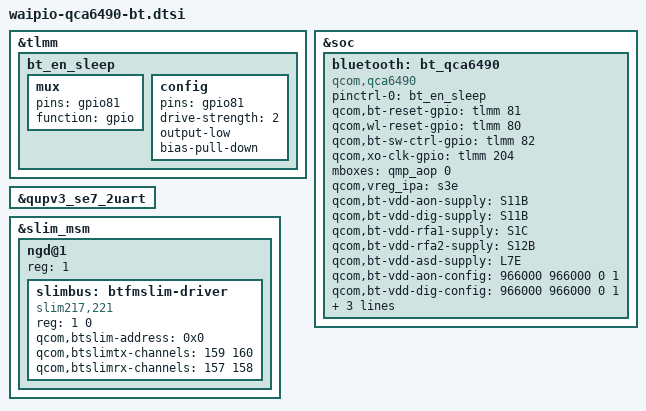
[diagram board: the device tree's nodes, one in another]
#include <dt-bindings/interconnect/qcom,waipio.h>

&tlmm {
	bt_en_sleep: bt_en_sleep {
		mux {
			pins = "gpio81";
			function = "gpio";
		};

		config {
			pins = "gpio81";
			drive-strength = <2>;
			output-low;
			bias-pull-down;
		};
	};
};

&soc {
	bluetooth: bt_qca6490 {
		compatible = "qcom,qca6490";
		pinctrl-names = "default";
		pinctrl-0 = <&bt_en_sleep>;
		qcom,bt-reset-gpio = <&tlmm 81 0>; /* BT_EN */
		qcom,wl-reset-gpio = <&tlmm 80 0>; /* WL_EN */
		qcom,bt-sw-ctrl-gpio = <&tlmm 82 0>; /* SW_CTRL */
		qcom,xo-clk-gpio = <&tlmm 204 0>; /* XO */
		mboxes = <&qmp_aop 0>;
		qcom,vreg_ipa = "s3e";

		qcom,bt-vdd-aon-supply = <&S11B>;
		qcom,bt-vdd-dig-supply = <&S11B>;
		qcom,bt-vdd-rfa1-supply = <&S1C>;
		qcom,bt-vdd-rfa2-supply = <&S12B>;
		qcom,bt-vdd-asd-supply = <&L7E>;

		qcom,bt-vdd-aon-config = <966000 966000 0 1>;
		qcom,bt-vdd-dig-config = <966000 966000 0 1>;
		qcom,bt-vdd-rfa1-config = <1900000 2100000 0 1>;
		qcom,bt-vdd-rfa2-config = <1350000 1350000 0 1>;
		qcom,bt-vdd-asd-config = <2800000 2800000 0 1>;
	};
};

&qupv3_se7_2uart {
	status = "ok";
};

&slim_msm {
	status =  "ok";

	#address-cells = <1>;
	#size-cells = <0>;

	ngd@1 {
		reg = <1>;
		#address-cells = <1>;
		#size-cells = <1>;

		/* slimbus child nodes */
		slimbus: btfmslim-driver {
			compatible = "slim217,221";
			reg = <1 0>;
			qcom,btslim-address  = <0x0>; /* BT SLIM EP address*/
			qcom,btslimtx-channels = <159 160>;
			qcom,btslimrx-channels = <157 158>;
		};
	};
};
